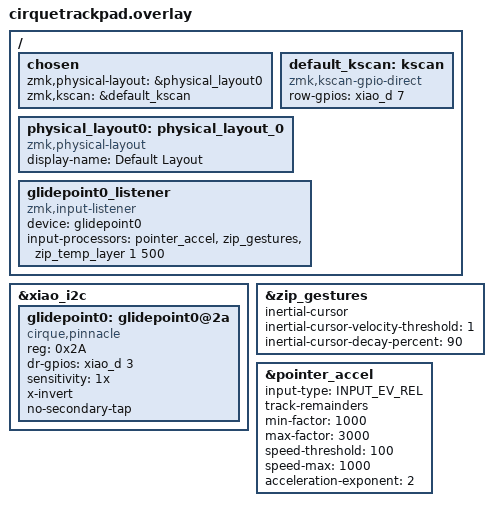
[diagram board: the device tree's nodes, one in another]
// cirquetrackpad.overlay
#include <dt-bindings/zmk/matrix_transform.h>
#include <physical_layouts.dtsi>
#include <input/processors.dtsi>
#include <dt-bindings/zmk/input_transform.h>
#include <behaviors/input_gestures_accel.dtsi>
#include <behaviors/input_processor_gestures.dtsi>

/ {
    chosen {
        zmk,physical-layout = &physical_layout0;
        zmk,kscan = &default_kscan;
    };

    default_kscan: kscan {
        compatible = "zmk,kscan-gpio-direct";
        row-gpios
            = <&xiao_d 7 (GPIO_ACTIVE_HIGH | GPIO_PULL_DOWN)> // Row A from the schematic file
            ;
    };
};

/ {
    physical_layout0: physical_layout_0 {
        compatible = "zmk,physical-layout";
        display-name = "Default Layout";
    };
};

&xiao_i2c {
    status = "okay";
    
    glidepoint0: glidepoint0@2a {
        compatible = "cirque,pinnacle";
        reg = <0x2A>;
        status = "okay";
        dr-gpios = <&xiao_d 3 (GPIO_ACTIVE_HIGH)>;

        sensitivity = "1x"; //1x, 2x, 3x, 4x
        //rotate-90;
        x-invert;
        //y-invert;
        //sleep;
        no-secondary-tap;
        //no-taps;
        //x-axis-z-min = 5; //default 5, malformed value error
        //y-axis-z-min = 4; // default 4, malformed value error
        
    };
};

&zip_gestures {
    // https://github.com/halfdane/zmk-input-gestures

    // Activate gestures and change their configuration as you see fit.
    // for details, see the section below that describes all gestures and
    // their configuration options.

    // This will create a mouseclick if your touch is short enough.
    // if you're running in relative mode and don't use no-taps, this might
    // result in duplicate taps

    //tap-detection;
    //tap-timout-ms=<120>;

    inertial-cursor;
    inertial-cursor-velocity-threshold=<1>;
    inertial-cursor-decay-percent=<90>;
};

&pointer_accel {
    // https://github.com/oleksandrmaslov/zmk-pointing-acceleration
    
    input-type = <INPUT_EV_REL>;  // For relative input devices
    track-remainders;             // Accumulate fractional movements
    min-factor = <1000>;          // 0.8x at very slow speeds
    max-factor = <3000>;         // 3.0x at fast speeds
    speed-threshold = <100>;     // counts/sec for 1x
    speed-max = <1000>;          // 6000 counts/sec for max accel
    acceleration-exponent = <2>;  // Quadratic acceleration curve
};

/ {
    glidepoint0_listener: glidepoint0_listener {
        compatible = "zmk,input-listener";
        status = "okay";
        device = <&glidepoint0>;
        input-processors = <
            &pointer_accel
            &zip_gestures
            &zip_temp_layer 1 500
	    	/*
            , <&zip_xy_scaler 2 1> // multiplier / divisor scaling
	    	, <&zip_xy_transform> (INPUT_TRANSFORM_X_INVERT)
            */
	    >;

    };

};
